# ATSAMA5D35 register map
Vendor: Atmel; Series: SAMA5D3; File version: 20130221
Registers are 32-bit, read-write, reset 0x0 unless marked. A register's access mark holds for its fields unless they carry their own. Offsets are from the block's base; [hi:lo] are bit positions; {n}, {i} and the like mark numbered series; 'fields as' and 'values as' point back to an identical list.

## UART0 — Universal Asynchronous Receiver Transmitter 0
Base 0xF0024000; register names take the prefix UART0_
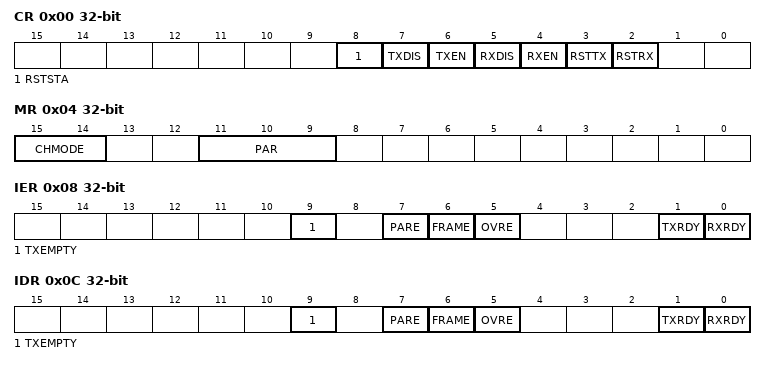
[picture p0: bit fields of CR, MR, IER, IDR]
0x00 CR wo reset not defined — Control Register
  [8] RSTSTA — Reset Status Bits
  [7] TXDIS — Transmitter Disable
  [6] TXEN — Transmitter Enable
  [5] RXDIS — Receiver Disable
  [4] RXEN — Receiver Enable
  [3] RSTTX — Reset Transmitter
  [2] RSTRX — Reset Receiver
0x04 MR — Mode Register
  [15:14] CHMODE — Channel Mode
    0=NORMAL (Normal Mode); 1=AUTOMATIC (Automatic Echo); 2=LOCAL_LOOPBACK; 3=REMOTE_LOOPBACK
  [11:9] PAR — Parity Type
    0=EVEN (Even Parity); 1=ODD (Odd Parity); 2=SPACE (Space: parity forced to 0); 3=MARK (Mark: parity forced to 1); 4=NO (No Parity)
0x08 IER wo reset not defined — Interrupt Enable Register
  [9] TXEMPTY — Enable TXEMPTY Interrupt
  [7] PARE — Enable Parity Error Interrupt
  [6] FRAME — Enable Framing Error Interrupt
  [5] OVRE — Enable Overrun Error Interrupt
  [1] TXRDY — Enable TXRDY Interrupt
  [0] RXRDY — Enable RXRDY Interrupt
0x0C IDR wo reset not defined — Interrupt Disable Register
  [9] TXEMPTY — Disable TXEMPTY Interrupt
  [7] PARE — Disable Parity Error Interrupt
  [6] FRAME — Disable Framing Error Interrupt
  [5] OVRE — Disable Overrun Error Interrupt
  [1] TXRDY — Disable TXRDY Interrupt
  [0] RXRDY — Disable RXRDY Interrupt
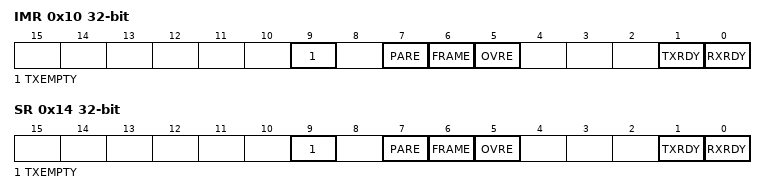
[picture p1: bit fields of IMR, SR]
0x10 IMR ro — Interrupt Mask Register
  [9] TXEMPTY — Mask TXEMPTY Interrupt
  [7] PARE — Mask Parity Error Interrupt
  [6] FRAME — Mask Framing Error Interrupt
  [5] OVRE — Mask Overrun Error Interrupt
  [1] TXRDY — Disable TXRDY Interrupt
  [0] RXRDY — Mask RXRDY Interrupt
0x14 SR ro reset not defined — Status Register
  [9] TXEMPTY — Transmitter Empty
  [7] PARE — Parity Error
  [6] FRAME — Framing Error
  [5] OVRE — Overrun Error
  [1] TXRDY — Transmitter Ready
  [0] RXRDY — Receiver Ready
0x18 RHR ro — Receive Holding Register
  [7:0] RXCHR — Received Character
0x1C THR wo reset not defined — Transmit Holding Register
  [7:0] TXCHR — Character to be Transmitted
0x20 BRGR — Baud Rate Generator Register
  [15:0] CD — Clock Divisor

## UART1 — Universal Asynchronous Receiver Transmitter 1
Base 0xF8028000; register names take the prefix UART1_
Registers as UART0.

## SFR — Special Function Registers
Base 0xF0038000; register names take the prefix SFR_
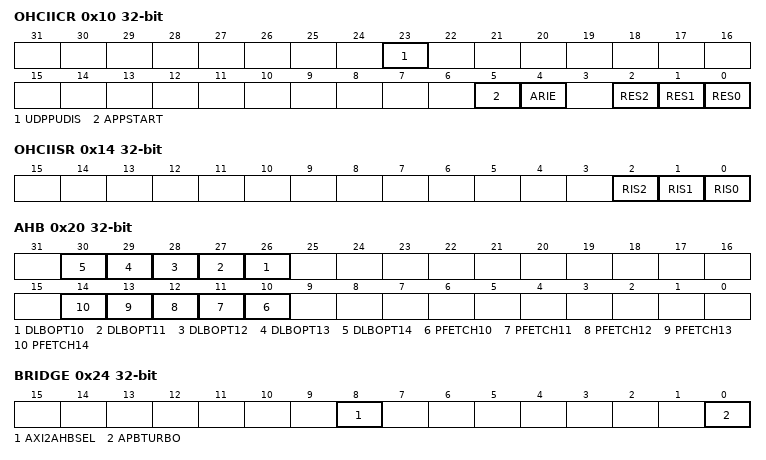
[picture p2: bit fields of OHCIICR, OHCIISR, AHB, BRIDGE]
0x10 OHCIICR — OHCI Interrupt Configuration Register
  [23] UDPPUDIS — OHCI USB DEVICE PULL-UP DISABLE
  [5] APPSTART — Reserved
  [4] ARIE — OHCI Asynchronous Resume Interrupt Enable
  [2] RES2 — USB PORTx RESET
  [1] RES1 — USB PORTx RESET
  [0] RES0 — USB PORTx RESET
0x14 OHCIISR ro reset not defined — OHCI Interrupt Status Register
  [2] RIS2 — OHCI Resume Interrupt Status Port 2
  [1] RIS1 — OHCI Resume Interrupt Status Port 1
  [0] RIS0 — OHCI Resume Interrupt Status Port 0
0x20 AHB — AHB Configuration Register
  [n+16] DLBOPT{n} (n=10..14) — AHB MASTERx {n} Converter Define Length Burst Optimization
  [n] PFETCH{n} (n=10..14) — AHB MASTERx {n} Converter Prefetch
    0=INCR4 (INCR undefined burst converted to burst of 4 beats.); 1=INCR8 (INCR undefined burst converted to burst of 8 beats.)
0x24 BRIDGE — Bridge Configuration Register
  [8] AXI2AHBSEL — AXI to AHB bridge for DDR controller selection
    0=SINGLE (use single port bridge.); 1=DUAL (use dual port bridge.)
  [0] APBTURBO — AHB to APB Bridge mode
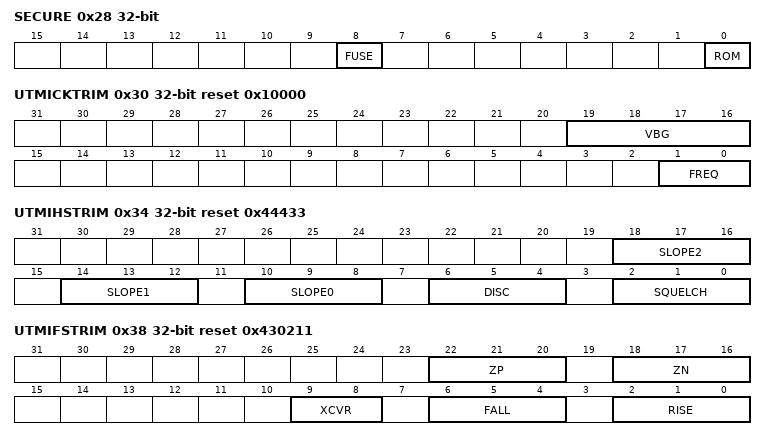
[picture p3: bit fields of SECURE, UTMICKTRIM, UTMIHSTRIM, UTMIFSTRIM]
0x28 SECURE — Security Configuration Register
  [8] FUSE — Disable Access to Fuse Controller
  [0] ROM — Disable Access to ROM Code
0x30 UTMICKTRIM reset 0x10000 — UTMI Clock Trimming Register
  [19:16] VBG — UTMI Band Gap Voltage Trimming
  [1:0] FREQ — UTMI Reference Clock Frequency
    0=12 MHz reference clock; 1=16 MHz reference clock; 2=24 MHz reference clock; 3=48 MHz reference clock
0x34 UTMIHSTRIM reset 0x44433 — UTMI High Speed Trimming Register
  [18:16] SLOPE2 — UTMI HS PORTx Transceiver Slope Trimming
  [14:12] SLOPE1 — UTMI HS PORTx Transceiver Slope Trimming
  [10:8] SLOPE0 — UTMI HS PORTx Transceiver Slope Trimming
  [6:4] DISC — UTMI Disconnect Voltage Trimming
  [2:0] SQUELCH — UTMI HS SQUELCH Voltage Trimming
0x38 UTMIFSTRIM reset 0x430211 — UTMI Full Speed Trimming Register
  [22:20] ZP — FS Transceiver PMOS impedance trimming
  [18:16] ZN — FS Transceiver NMOS impedance trimming
  [9:8] XCVR — FS Transceiver crossover voltage trimming
  [6:4] FALL — FS Transceiver output falling slope trimming
  [2:0] RISE — FS Transceiver output rising slope trimming
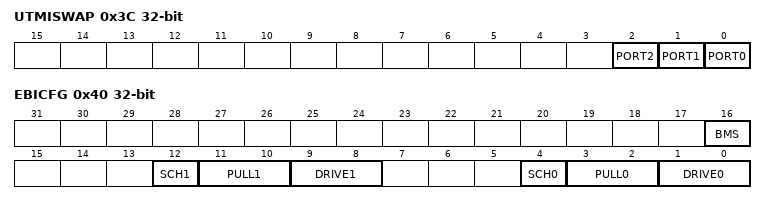
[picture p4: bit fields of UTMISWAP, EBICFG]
0x3C UTMISWAP — UTMI DP/DM Pin Swapping Register
  [all] fields
    0=NORMAL (DP/DM normal pinout.); 1=SWAPPED (DP/DM swapped pinout.)
  [2] PORT2 — PORT 2 DP/DM Pin Swapping
  [1] PORT1 — PORT 1 DP/DM Pin Swapping
  [0] PORT0 — PORT 0 DP/DM Pin Swapping
0x40 EBICFG reset not defined — EBI Configuration Register
  [16] BMS — BMS Sampled Value (Read Only)
    0=ROM (Boot on ROM.); 1=EBI (Boot on EBI.)
  [12] SCH1 — EBI Pins Schmitt Trigger
  [11:10] PULL1 — EBI Pins Pull Value
    0=UP (Pull-up); 1=NONE (No Pull); 3=DOWN (Pull-down)
  [9:8] DRIVE1 — EBI Pins Drive Level
    0=LOW (Low drive level); 2=MEDIUM (Medium drive level); 3=HIGH (High drive level)
  [4] SCH0 — EBI Pins Schmitt Trigger
  [3:2] PULL0 — EBI Pins Pull Value
    0=UP (Pull-up); 1=NONE (No Pull); 3=DOWN (Pull-down)
  [1:0] DRIVE0 — EBI Pins Drive Level
    values as DRIVE1
